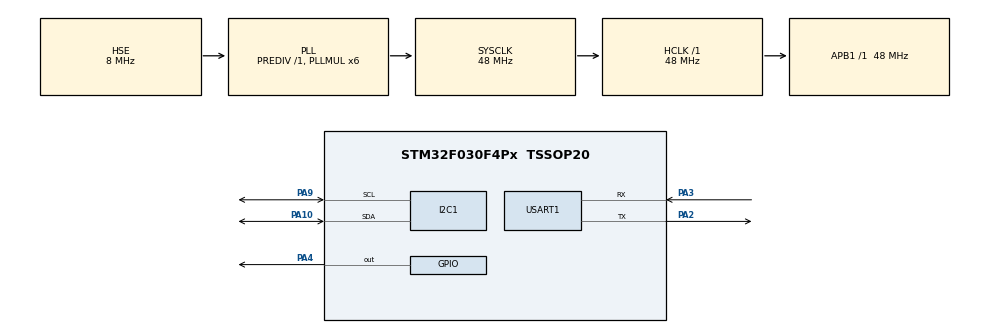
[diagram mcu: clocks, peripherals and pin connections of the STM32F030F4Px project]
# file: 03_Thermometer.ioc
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I2C1.Timing=0x10805D88
Mcu.Family=STM32F0
Mcu.Name=STM32F030F4Px
Mcu.Package=TSSOP20
PA10.Mode=I2C
PA10.Signal=I2C1_SDA
PA13.Mode=Serial_Wire
PA13.Signal=SYS_SWDIO
PA14.Mode=Serial_Wire
PA14.Signal=SYS_SWCLK
PA2.Mode=Asynchronous
PA2.Signal=USART1_TX
PA3.Mode=Asynchronous
PA3.Signal=USART1_RX
PA4.Signal=GPIO_Output
PA9.Mode=I2C
PA9.Signal=I2C1_SCL
PF0-OSC_IN.Mode=HSE-External-Oscillator
PF0-OSC_IN.Signal=RCC_OSC_IN
PF1-OSC_OUT.Mode=HSE-External-Oscillator
PF1-OSC_OUT.Signal=RCC_OSC_OUT
ProjectManager.HeapSize=0x200
ProjectManager.StackSize=0x400
ProjectManager.TargetToolchain=MDK-ARM V5.32
RCC.AHBFreq_Value=48000000
RCC.APB1Freq_Value=48000000
RCC.APB1TimFreq_Value=48000000
RCC.HCLKFreq_Value=48000000
RCC.I2c1ClockSelection=RCC_I2C1CLKSOURCE_SYSCLK
RCC.PLLMUL=RCC_PLL_MUL6
RCC.PLLSourceVirtual=RCC_PLLSOURCE_HSE
RCC.SYSCLKFreq_VALUE=48000000
RCC.SYSCLKSource=RCC_SYSCLKSOURCE_PLLCLK
USART1.VirtualMode-Asynchronous=VM_ASYNC
board=custom

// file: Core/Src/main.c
/* USER CODE BEGIN Header */
/**
  ******************************************************************************
  * @file           : main.c
  * @brief          : Main program body
  ******************************************************************************
  * @attention
  *
  * Copyright (c) 2025 STMicroelectronics.
  * All rights reserved.
  *
  * This software is licensed under terms that can be found in the LICENSE file
  * in the root directory of this software component.
  * If no LICENSE file comes with this software, it is provided AS-IS.
  *
  ******************************************************************************
  */
/* USER CODE END Header */
#include "main.h"
#include "i2c.h"
#include "usart.h"
#include "gpio.h"

/* USER CODE BEGIN Includes */
#include "thermometer.h"
/* USER CODE END Includes */

void SystemClock_Config(void);

int main(void)
{

  /* MCU Configuration--------------------------------------------------------*/

  /* Reset of all peripherals, Initializes the Flash interface and the Systick. */
  HAL_Init();

  /* Configure the system clock */
  SystemClock_Config();

  /* Initialize all configured peripherals */
  MX_GPIO_Init();
  MX_I2C1_Init();
  MX_USART1_UART_Init();
  /* USER CODE BEGIN 2 */
	run_thermometer();
  /* USER CODE END 2 */

  /* Infinite loop */
  while (1)
  {

  }
}

void SystemClock_Config(void)
{
  RCC_OscInitTypeDef RCC_OscInitStruct = {0};
  RCC_ClkInitTypeDef RCC_ClkInitStruct = {0};
  RCC_PeriphCLKInitTypeDef PeriphClkInit = {0};

  /** Initializes the RCC Oscillators according to the specified parameters
  * in the RCC_OscInitTypeDef structure.
  */
  RCC_OscInitStruct.OscillatorType = RCC_OSCILLATORTYPE_HSE;
  RCC_OscInitStruct.HSEState = RCC_HSE_ON;
  RCC_OscInitStruct.PLL.PLLState = RCC_PLL_ON;
  RCC_OscInitStruct.PLL.PLLSource = RCC_PLLSOURCE_HSE;
  RCC_OscInitStruct.PLL.PLLMUL = RCC_PLL_MUL6;
  RCC_OscInitStruct.PLL.PREDIV = RCC_PREDIV_DIV1;
  if (HAL_RCC_OscConfig(&RCC_OscInitStruct) != HAL_OK)
  {
    Error_Handler();
  }

  /** Initializes the CPU, AHB and APB buses clocks
  */
  RCC_ClkInitStruct.ClockType = RCC_CLOCKTYPE_HCLK|RCC_CLOCKTYPE_SYSCLK
                              |RCC_CLOCKTYPE_PCLK1;
  RCC_ClkInitStruct.SYSCLKSource = RCC_SYSCLKSOURCE_PLLCLK;
  RCC_ClkInitStruct.AHBCLKDivider = RCC_SYSCLK_DIV1;
  RCC_ClkInitStruct.APB1CLKDivider = RCC_HCLK_DIV1;

  if (HAL_RCC_ClockConfig(&RCC_ClkInitStruct, FLASH_LATENCY_1) != HAL_OK)
  {
    Error_Handler();
  }
  PeriphClkInit.PeriphClockSelection = RCC_PERIPHCLK_USART1|RCC_PERIPHCLK_I2C1;
  PeriphClkInit.Usart1ClockSelection = RCC_USART1CLKSOURCE_PCLK1;
  PeriphClkInit.I2c1ClockSelection = RCC_I2C1CLKSOURCE_SYSCLK;
  if (HAL_RCCEx_PeriphCLKConfig(&PeriphClkInit) != HAL_OK)
  {
    Error_Handler();
  }
}

/* USER CODE BEGIN 4 */
/**
  * @brief  This function is needed to enable printf through UART.
	* @input some character to send
  * @retval same as input
  */
int fputc(int ch, FILE *f) {
    HAL_UART_Transmit(&huart1, (uint8_t *)&ch, 1, HAL_MAX_DELAY);
    return ch;
}
/* USER CODE END 4 */

void Error_Handler(void)
{
  __disable_irq();
  while (1)
  {
  }
}
